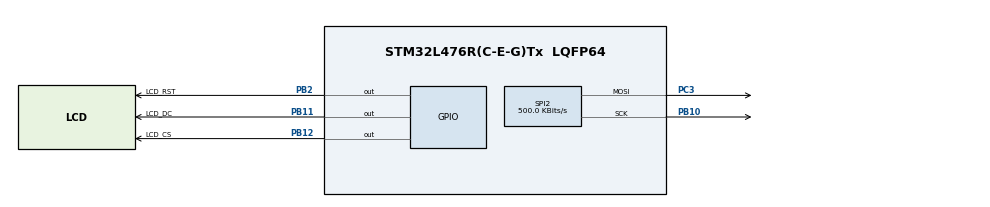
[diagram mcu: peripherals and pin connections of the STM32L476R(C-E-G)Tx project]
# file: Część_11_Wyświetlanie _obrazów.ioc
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Mcu.Family=STM32L4
Mcu.Name=STM32L476R(C-E-G)Tx
Mcu.Package=LQFP64
NVIC.PriorityGroup=NVIC_PRIORITYGROUP_4
PB10.Mode=TX_Only_Simplex_Unidirect_Master
PB10.Signal=SPI2_SCK
PB11.GPIO_Label=LCD_DC
PB11.Signal=GPIO_Output
PB12.GPIO_Label=LCD_CS
PB12.PinState=GPIO_PIN_SET
PB12.Signal=GPIO_Output
PB2.GPIO_Label=LCD_RST
PB2.Signal=GPIO_Output
PC3.Mode=TX_Only_Simplex_Unidirect_Master
PC3.Signal=SPI2_MOSI
ProjectManager.HeapSize=0x200
ProjectManager.StackSize=0x400
ProjectManager.TargetToolchain=STM32CubeIDE
RCC.HSE_VALUE=8000000
RCC.HSI_VALUE=16000000
RCC.LSE_VALUE=32768
RCC.MSI_VALUE=4000000
RCC.VCOOutputFreq_Value=32000000
SPI2.BaudRatePrescaler=SPI_BAUDRATEPRESCALER_8
SPI2.CalculateBaudRate=500.0 KBits/s
SPI2.DataSize=SPI_DATASIZE_8BIT
SPI2.Direction=SPI_DIRECTION_2LINES
SPI2.Mode=SPI_MODE_MASTER
SPI2.NSSPMode=SPI_NSS_PULSE_DISABLE
SPI2.VirtualType=VM_MASTER
board=custom

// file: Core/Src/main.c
/* USER CODE BEGIN Header */
/**
  ******************************************************************************
  * @file           : main.c
  * @brief          : Main program body
  ******************************************************************************
  * @attention
  *
  * Copyright (c) 2026 STMicroelectronics.
  * All rights reserved.
  *
  * This software is licensed under terms that can be found in the LICENSE file
  * in the root directory of this software component.
  * If no LICENSE file comes with this software, it is provided AS-IS.
  *
  ******************************************************************************
  */
/* USER CODE END Header */
#include "main.h"
#include "spi.h"
#include "gpio.h"
#include "lcd.h"
#include "forbot_logo.c"

void SystemClock_Config(void);

int main(void)
{

  /* MCU Configuration--------------------------------------------------------*/

  /* Reset of all peripherals, Initializes the Flash interface and the Systick. */
  HAL_Init();

  /* Configure the system clock */
  SystemClock_Config();

  /* Initialize all configured peripherals */
  MX_GPIO_Init();
  MX_SPI2_Init();

  /* Infinite loop */
  /* USER CODE BEGIN WHILE */
  lcd_init();
  lcd_fill_box(0, 0, 160, 16, RED);
  lcd_fill_box(0, 16, 160, 16, GREEN);
  lcd_fill_box(0, 32, 160, 16, BLUE);
  lcd_fill_box(0, 48, 160, 16, YELLOW);
  lcd_fill_box(0, 64, 160, 16, MAGENTA);
  lcd_fill_box(0, 80, 160, 16, CYAN);
  lcd_fill_box(0, 96, 160, 16, WHITE);
  lcd_fill_box(0, 112, 160, 16, BLACK);
  for (int i = 0; i < 128; i++) {
    lcd_put_pixel(i, i, RED);
    lcd_put_pixel(127 - i, i, RED);
  }
  lcd_draw_image(35, 20, 100, 80, forbot_logo);

  while (1)
  {
    /* USER CODE END WHILE */

  }
}

void SystemClock_Config(void)
{
  RCC_OscInitTypeDef RCC_OscInitStruct = {0};
  RCC_ClkInitTypeDef RCC_ClkInitStruct = {0};

  /** Configure the main internal regulator output voltage
  */
  if (HAL_PWREx_ControlVoltageScaling(PWR_REGULATOR_VOLTAGE_SCALE1) != HAL_OK)
  {
    Error_Handler();
  }

  /** Initializes the RCC Oscillators according to the specified parameters
  * in the RCC_OscInitTypeDef structure.
  */
  RCC_OscInitStruct.OscillatorType = RCC_OSCILLATORTYPE_MSI;
  RCC_OscInitStruct.MSIState = RCC_MSI_ON;
  RCC_OscInitStruct.MSICalibrationValue = 0;
  RCC_OscInitStruct.MSIClockRange = RCC_MSIRANGE_6;
  RCC_OscInitStruct.PLL.PLLState = RCC_PLL_NONE;
  if (HAL_RCC_OscConfig(&RCC_OscInitStruct) != HAL_OK)
  {
    Error_Handler();
  }

  /** Initializes the CPU, AHB and APB buses clocks
  */
  RCC_ClkInitStruct.ClockType = RCC_CLOCKTYPE_HCLK|RCC_CLOCKTYPE_SYSCLK
                              |RCC_CLOCKTYPE_PCLK1|RCC_CLOCKTYPE_PCLK2;
  RCC_ClkInitStruct.SYSCLKSource = RCC_SYSCLKSOURCE_MSI;
  RCC_ClkInitStruct.AHBCLKDivider = RCC_SYSCLK_DIV1;
  RCC_ClkInitStruct.APB1CLKDivider = RCC_HCLK_DIV1;
  RCC_ClkInitStruct.APB2CLKDivider = RCC_HCLK_DIV1;

  if (HAL_RCC_ClockConfig(&RCC_ClkInitStruct, FLASH_LATENCY_0) != HAL_OK)
  {
    Error_Handler();
  }
}

void Error_Handler(void)
{
  __disable_irq();
  while (1)
  {
  }
}
